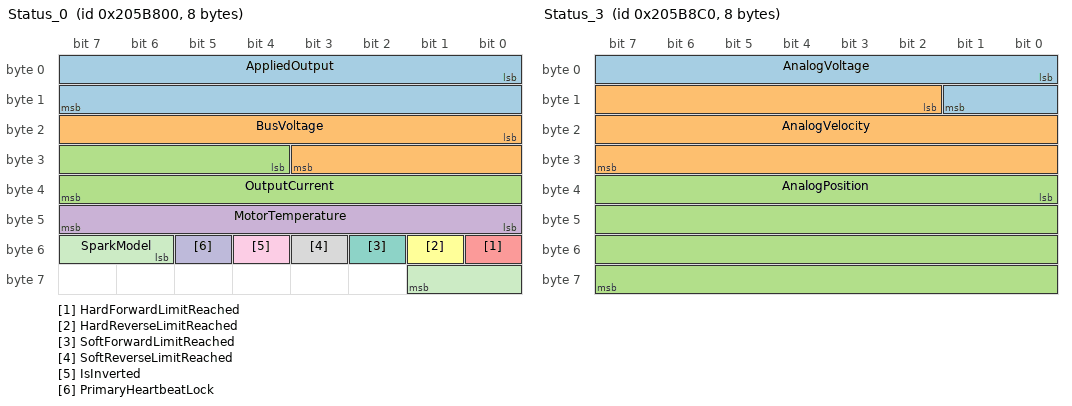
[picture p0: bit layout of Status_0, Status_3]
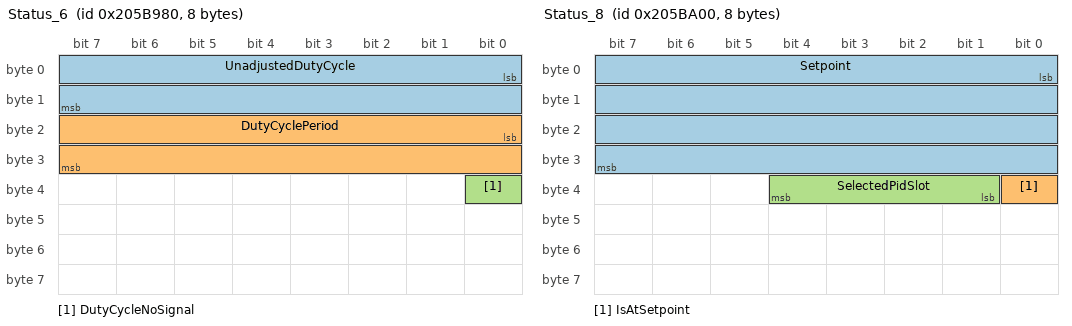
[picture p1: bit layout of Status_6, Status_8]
VERSION "2.1.0"

// REV Robotics SPARK MAX / SPARK Flex periodic status frames, firmware 25 and later
// (API class 46), as REVLib 2026 and later records them in .revlog files.
//
// Source: REV's published SPARK frame specification, REV-Specs
// can-frames/spark-frames-2.1.0 (https://github.com/REVrobotics/REV-Specs), which REV's
// node-revlog-converter also encodes (src/resources/spark.public.dbc, BSD-3-Clause,
// Copyright (c) 2025, REV Robotics). Field positions, widths, types, and scale factors follow
// that specification; names are rewritten in CamelCase, and reserved bits are omitted.
//
// CAN arbitration ID (29-bit extended):
//   Bits 28-24: Device type (2 = SPARK)
//   Bits 23-16: Manufacturer (5 = REV)
//   Bits 15-10: API class (46 = periodic status)
//   Bits 9-6:   API index (status frame number)
//   Bits 5-0:   Device CAN ID
// Base IDs below are for device 0; the decoder ignores the device bits.
//
// Firmware 25+ still sends the legacy status 0 frame (API class 6, index 0) once a second for
// old followers, with applied output always 0 and every fault set: it carries no data and is
// deliberately not defined here.
//
// Velocity and position are in RPM and rotations by default; a conversion factor configured on
// the SPARK changes them (the units say so).

// Status 0 (10 ms): applied output, bus voltage, current, temperature, limits, and the model
// (SPARK_MODEL, bits 54-57: 1 = SPARK Flex, 2 = SPARK MAX, 0 = unknown, the codes of REVLib's
// SparkLowLevel.SparkModel)
BO_ 0x0205B800 Status_0: 8 Spark
 SG_ AppliedOutput : 0|16@1- (0.00003082369457075716,0) [-1|1] "duty_cycle"
 SG_ BusVoltage : 16|12@1+ (0.0073260073260073,0) [0|30] "V"
 SG_ OutputCurrent : 28|12@1+ (0.0366300366300366,0) [0|150] "A"
 SG_ MotorTemperature : 40|8@1+ (1,0) [0|255] "degC"
 SG_ HardForwardLimitReached : 48|1@1+ (1,0) [0|1] ""
 SG_ HardReverseLimitReached : 49|1@1+ (1,0) [0|1] ""
 SG_ SoftForwardLimitReached : 50|1@1+ (1,0) [0|1] ""
 SG_ SoftReverseLimitReached : 51|1@1+ (1,0) [0|1] ""
 SG_ IsInverted : 52|1@1+ (1,0) [0|1] ""
 SG_ PrimaryHeartbeatLock : 53|1@1+ (1,0) [0|1] ""
 SG_ SparkModel : 54|4@1+ (1,0) [0|15] ""

// Status 1 (250 ms): faults, warnings, and their sticky versions; follower
BO_ 0x0205B840 Status_1: 8 Spark
 SG_ OtherFault : 0|1@1+ (1,0) [0|1] ""
 SG_ MotorTypeFault : 1|1@1+ (1,0) [0|1] ""
 SG_ SensorFault : 2|1@1+ (1,0) [0|1] ""
 SG_ CanFault : 3|1@1+ (1,0) [0|1] ""
 SG_ TemperatureFault : 4|1@1+ (1,0) [0|1] ""
 SG_ DrvFault : 5|1@1+ (1,0) [0|1] ""
 SG_ EscEepromFault : 6|1@1+ (1,0) [0|1] ""
 SG_ FirmwareFault : 7|1@1+ (1,0) [0|1] ""
 SG_ BrownoutWarning : 16|1@1+ (1,0) [0|1] ""
 SG_ OvercurrentWarning : 17|1@1+ (1,0) [0|1] ""
 SG_ EscEepromWarning : 18|1@1+ (1,0) [0|1] ""
 SG_ ExtEepromWarning : 19|1@1+ (1,0) [0|1] ""
 SG_ SensorWarning : 20|1@1+ (1,0) [0|1] ""
 SG_ StallWarning : 21|1@1+ (1,0) [0|1] ""
 SG_ HasResetWarning : 22|1@1+ (1,0) [0|1] ""
 SG_ OtherWarning : 23|1@1+ (1,0) [0|1] ""
 SG_ OtherStickyFault : 24|1@1+ (1,0) [0|1] ""
 SG_ MotorTypeStickyFault : 25|1@1+ (1,0) [0|1] ""
 SG_ SensorStickyFault : 26|1@1+ (1,0) [0|1] ""
 SG_ CanStickyFault : 27|1@1+ (1,0) [0|1] ""
 SG_ TemperatureStickyFault : 28|1@1+ (1,0) [0|1] ""
 SG_ DrvStickyFault : 29|1@1+ (1,0) [0|1] ""
 SG_ EscEepromStickyFault : 30|1@1+ (1,0) [0|1] ""
 SG_ FirmwareStickyFault : 31|1@1+ (1,0) [0|1] ""
 SG_ BrownoutStickyWarning : 40|1@1+ (1,0) [0|1] ""
 SG_ OvercurrentStickyWarning : 41|1@1+ (1,0) [0|1] ""
 SG_ EscEepromStickyWarning : 42|1@1+ (1,0) [0|1] ""
 SG_ ExtEepromStickyWarning : 43|1@1+ (1,0) [0|1] ""
 SG_ SensorStickyWarning : 44|1@1+ (1,0) [0|1] ""
 SG_ StallStickyWarning : 45|1@1+ (1,0) [0|1] ""
 SG_ HasResetStickyWarning : 46|1@1+ (1,0) [0|1] ""
 SG_ OtherStickyWarning : 47|1@1+ (1,0) [0|1] ""
 SG_ IsFollower : 48|1@1+ (1,0) [0|1] ""

// Status 2 (20 ms): primary encoder
BO_ 0x0205B880 Status_2: 8 Spark
 SG_ Velocity : 0|32@1- (1,0) [0|0] "rpm unless converted"
 SG_ Position : 32|32@1- (1,0) [0|0] "rotations unless converted"

// Status 3 (20 ms): analog sensor
BO_ 0x0205B8C0 Status_3: 8 Spark
 SG_ AnalogVoltage : 0|10@1+ (0.0048973607038123,0) [0|5] "V"
 SG_ AnalogVelocity : 10|22@1- (0.007812026887906498,0) [0|0] "rpm unless converted"
 SG_ AnalogPosition : 32|32@1- (1,0) [0|0] "rotations unless converted"

// Status 4 (20 ms): external encoder (SPARK Flex) or alternate encoder (SPARK MAX)
BO_ 0x0205B900 Status_4: 8 Spark
 SG_ ExternalEncoderVelocity : 0|32@1- (1,0) [0|0] "rpm unless converted"
 SG_ ExternalEncoderPosition : 32|32@1- (1,0) [0|0] "rotations unless converted"

// Status 5 (20 ms): duty-cycle absolute encoder
BO_ 0x0205B940 Status_5: 8 Spark
 SG_ DutyCycleEncoderVelocity : 0|32@1- (1,0) [0|0] "rpm unless converted"
 SG_ DutyCycleEncoderPosition : 32|32@1- (1,0) [0|0] "rotations unless converted"

// Status 6 (20 ms): duty-cycle absolute encoder, raw
BO_ 0x0205B980 Status_6: 8 Spark
 SG_ UnadjustedDutyCycle : 0|16@1+ (0.00001541161211566339,0) [0|1] ""
 SG_ DutyCyclePeriod : 16|16@1+ (1,0) [0|65535] "us"
 SG_ DutyCycleNoSignal : 32|1@1+ (1,0) [0|1] ""

// Status 7 (20 ms): closed-loop integral accumulator
BO_ 0x0205B9C0 Status_7: 8 Spark
 SG_ IAccum : 0|32@1- (1,0) [0|0] ""

// Status 8 (20 ms): closed-loop setpoint
BO_ 0x0205BA00 Status_8: 8 Spark
 SG_ Setpoint : 0|32@1- (1,0) [0|0] ""
 SG_ IsAtSetpoint : 32|1@1+ (1,0) [0|1] ""
 SG_ SelectedPidSlot : 33|4@1+ (1,0) [0|15] ""

// Status 9 (100 ms): MAXMotion intermediate setpoints
BO_ 0x0205BA40 Status_9: 8 Spark
 SG_ MaxMotionPositionSetpoint : 0|32@1- (1,0) [0|0] ""
 SG_ MaxMotionVelocitySetpoint : 32|32@1- (1,0) [0|0] ""

SIG_VALTYPE_ 0x0205B880 Velocity : 1;
SIG_VALTYPE_ 0x0205B880 Position : 1;
SIG_VALTYPE_ 0x0205B8C0 AnalogPosition : 1;
SIG_VALTYPE_ 0x0205B900 ExternalEncoderVelocity : 1;
SIG_VALTYPE_ 0x0205B900 ExternalEncoderPosition : 1;
SIG_VALTYPE_ 0x0205B940 DutyCycleEncoderVelocity : 1;
SIG_VALTYPE_ 0x0205B940 DutyCycleEncoderPosition : 1;
SIG_VALTYPE_ 0x0205B9C0 IAccum : 1;
SIG_VALTYPE_ 0x0205BA00 Setpoint : 1;
SIG_VALTYPE_ 0x0205BA40 MaxMotionPositionSetpoint : 1;
SIG_VALTYPE_ 0x0205BA40 MaxMotionVelocitySetpoint : 1;
